# MDR_MLDR155 register map
Vendor: Milandr; Series: ARMCM4; File version: 2.0
CPU: CM4 r0p0, little endian, MPU, FPU, 3 interrupt priority bits
Registers are 32-bit, read-write, reset 0x0 unless marked. A register's access mark holds for its fields unless they carry their own. Offsets are from the block's base; [hi:lo] are bit positions; {n}, {i} and the like mark numbered series; 'fields as' and 'values as' point back to an identical list.

## MDR_UART1 — UART Control
Base 0x4008D000
Same registers: MDR_UART2 0x4008E000, MDR_UART3 0x4008F000, MDR_UART4 0x40090000
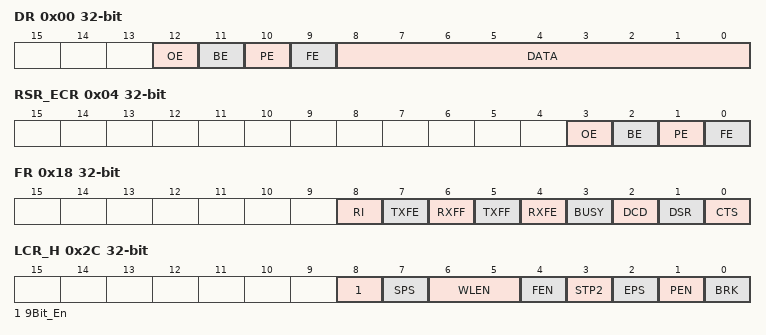
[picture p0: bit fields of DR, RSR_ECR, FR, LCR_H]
0x00 DR — Data Register
  [12] OE — Overrun FIFO_RX
    0=Ok (No Error); 1=ERROR (Error is active)
  [11] BE — Break Error
    0=Ok (No Error); 1=ERROR (Error is active)
  [10] PE — Parity Error
    0=Ok (No Error); 1=ERROR (Error is active)
  [9] FE — Stop Bit Error
    0=Ok (No Error); 1=ERROR (Error is active)
  [8:0] DATA — Data FIFO access
0x04 RSR_ECR — Receive Status and Error Clear Register
  [all] fields
    0=Ok (No Error); 1=ERROR (Error is active)
  [3] OE — Overrun FIFO_RX
  [2] BE — Break Error
  [1] PE — Parity Error
  [0] FE — Stop Bit Error
0x18 FR ro — Flag Register
  [8] RI — Modem Ring Indicator
    0=Inactive (Modem line is High); 1=Active (Modem line is Low)
  [7] TXFE — FIFO_RX Empty status
    0=Inactive (FIFO not Empty); 1=Empty (FIFO Empty)
  [6] RXFF — FIFO_RX Full Status
    0=Inactive (FIFO not Full); 1=Full (FIFO Full)
  [5] TXFF — FIFO_TX Full Status
    0=Inactive (FIFO not Full); 1=Full (FIFO Full)
  [4] RXFE — FIFO_RX Empty status
    0=Inactive (FIFO not Empty); 1=Empty (FIFO Empty)
  [3] BUSY — Transmitting data
    0=Off (Inactive); 1=On (Active)
  [2] DCD — Modem Data Carrier Detect
    values as RI
  [1] DSR — Modem Data Set Ready
    values as RI
  [0] CTS — Modem Clear To Send
    values as RI
0x20 ILPR — IrDA Low-Power Counter
  [7:0] DVSR — Div of SampleRate
0x24 IBRD — Integer BaudRate Divisor
  [15:0] Baud_DivInt — Integer part of Rate divisor
0x28 FBRD — Fractional BaudRate Divisor
  [5:0] Baud_DivFrac — Fractional part of Rate divisor
0x2C LCR_H — Line Control Register
  [8] 9Bit_En — Enable 9bit length mode
    0=byWLEN (Length by WLEN field); 1=9bit length
  [7] SPS — Stick Parity Select
    0=Off (Disabled); 1=On (Enabled)
  [6:5] WLEN — Word Length
    {v}=bit_{v+5} (Word bits length) (v=0..3)
  [4] FEN — FIFOs Enable
    0=Off (Disabled); 1=On (Enabled)
  [3] STP2 — Double Stop Bits Enable
    0=Off (Disabled); 1=On (Enabled)
  [2] EPS — Even Parity Select
    0=Odd (Odd parity bit); 1=Even parity bit
  [1] PEN — Parity Enable
    0=Off (Disabled); 1=On (Enabled)
  [0] BRK — Send Break - TX LOW for 2 words
    0=Off (Disabled); 1=On (Enabled)
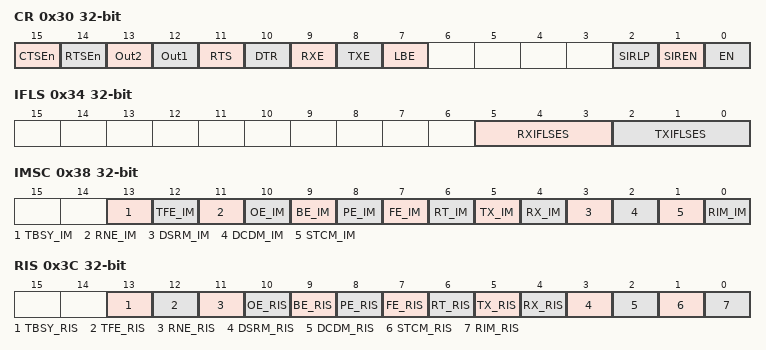
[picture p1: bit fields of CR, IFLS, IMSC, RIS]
0x30 CR — Control Register
  [15] CTSEn — Hardware CTS Control
    0=Off (Disabled); 1=On (Enabled)
  [14] RTSEn — Hardware RTS Control
    0=Off (Disabled); 1=On (Enabled)
  [13] Out2 — Custom Modem Output2 - RI
    0=Inactive (Sets modem line to Inactive); 1=Active (Sets modem line to Active)
  [12] Out1 — Custom Modem Output1 - DCD
    values as Out2
  [11] RTS — Request To Send
    values as Out2
  [10] DTR — Data Transmit Ready
    values as Out2
  [9] RXE — Receiver Enable
    0=Off (Disabled); 1=On (Enabled)
  [8] TXE — Transmitter Enable
    0=Off (Disabled); 1=On (Enabled)
  [7] LBE — LoopBack Enable
    0=Off (Disabled); 1=On (Enabled)
  [2] SIRLP — IrDA Low-Power Enable
    0=Off (Disabled); 1=On (Enabled)
  [1] SIREN — IrDA Enable
    0=Off (Disabled); 1=On (Enabled)
  [0] EN — Enable UART
    0=Off (Disabled); 1=On (Enabled)
0x34 IFLS — IRQ FIFO Level
  [5:3] RXIFLSES — IRQ FIFO_RX level
    0=Words_ge4 (Greater or Equal words in FIFO_RX); 1=Words_ge8 (Greater or Equal words in FIFO_RX); 2=Words_ge16 (Greater or Equal words in FIFO_RX); 3=Words_ge24 (Greater or Equal words in FIFO_RX); 4=Words_ge32 (Greater or Equal words in FIFO_RX)
  [2:0] TXIFLSES — IRQ FIFO_TX level
    0=Words_le4 (Less or Equal words in FIFO_TX); 1=Words_le8 (Less or Equal words in FIFO_TX); 2=Words_le16 (Less or Equal words in FIFO_TX); 3=Words_le24 (Less or Equal words in FIFO_TX); 4=Words_le32 (Less or Equal words in FIFO_TX)
0x38 IMSC (reset mask 0x7FF) — IRQ Mask Set Clear
  [all] fields
    0=Off (IRQ Disabled); 1=On (IRQ Enabled)
  [13] TBSY_IM — TX data in shift register
  [12] TFE_IM — FIFO_TX empty
  [11] RNE_IM — FIFO_RX not Empty
  [10] OE_IM — Overrun FIFO_RX IRQ Mask
  [9] BE_IM — BreakLine IRQ Mask
  [8] PE_IM — Parity Error IRQ Mask
  [7] FE_IM — Frame Error IRQ Mask
  [6] RT_IM — RX Timeout IRQ Mask
  [5] TX_IM — TX IRQ Mask
  [4] RX_IM — RX IRQ Mask
  [3] DSRM_IM — DSR Modem IRQ Mask
  [2] DCDM_IM — DCD Modem IRQ Mask
  [1] STCM_IM — STC Modem IRQ Mask
  [0] RIM_IM — RI Modem IRQ Mask
0x3C RIS ro — Raw IQR Status Register
  [all] fields
    0=Off (Event Inactive); 1=On (Event Active)
  [13] TBSY_RIS — TX data in shift register
  [12] TFE_RIS — FIFO_TX empty
  [11] RNE_RIS — FIFO_RX not Empty
  [10] OE_RIS — Overrun FIFO_RX Event
  [9] BE_RIS — BreakLine Event
  [8] PE_RIS — Parity Error Event
  [7] FE_RIS — Frame Error Event
  [6] RT_RIS — RX Timeout Event
  [5] TX_RIS — TX Event
  [4] RX_RIS — RX Event
  [3] DSRM_RIS — DSR Modem Event
  [2] DCDM_RIS — DCD Modem Event
  [1] STCM_RIS — STC Modem Event
  [0] RIM_RIS — RI Modem Event
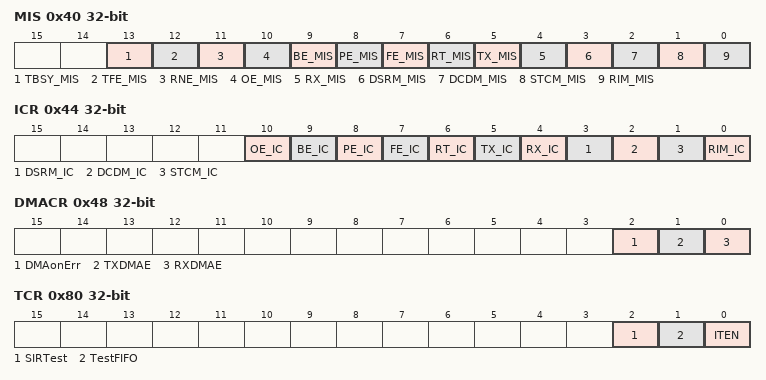
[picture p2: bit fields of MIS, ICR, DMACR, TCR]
0x40 MIS ro — Masked IQR Status Register
  [all] fields
    0=Off (Event Inactive); 1=On (Event Active)
  [13] TBSY_MIS — TX data in shift register
  [12] TFE_MIS — FIFO_TX empty
  [11] RNE_MIS — FIFO_RX not Empty
  [10] OE_MIS — Overrun FIFO_RX Event
  [9] BE_MIS — BreakLine Event
  [8] PE_MIS — Parity Error Event
  [7] FE_MIS — Frame Error Event
  [6] RT_MIS — RX Timeout Event
  [5] TX_MIS — TX Event
  [4] RX_MIS — RX Event
  [3] DSRM_MIS — DSR Modem Event
  [2] DCDM_MIS — DCD Modem Event
  [1] STCM_MIS — STC Modem Event
  [0] RIM_MIS — RI Modem Event
0x44 ICR wo — IRQ Clear Register
  [all] fields
    0=Inactive state; 1=Clear event
  [10] OE_IC — Overrun FIFO_RX Event
  [9] BE_IC — BreakLine Event
  [8] PE_IC — Parity Error Event
  [7] FE_IC — Frame Error Event
  [6] RT_IC — RX Timeout Event
  [5] TX_IC — TX Event
  [4] RX_IC — RX Event
  [3] DSRM_IC — DSR Modem Event
  [2] DCDM_IC — DCD Modem Event
  [1] STCM_IC — STC Modem Event
  [0] RIM_IC — RI Modem Event
0x48 DMACR — DMA Control Register
  [2] DMAonErr — Disable DMA req on Error
    0=Ignore Errors; 1=StopOnError (SReq and Req disable on Error)
  [1] TXDMAE — TX DMA Enable
    0=Disabled (DMA disabled); 1=Enabled (DMA enabled)
  [0] RXDMAE — RX DMA Enable
    0=Disabled (DMA disabled); 1=Enabled (DMA enabled)
0x80 TCR — Test Control Register
  [all] fields
    0=Disabled (Normal operation); 1=Enabled (Testing Mode)
  [2] SIRTest — IrDA test mode
  [1] TestFIFO — FIFO test mode
  [0] ITEN — Test Mode Enable
